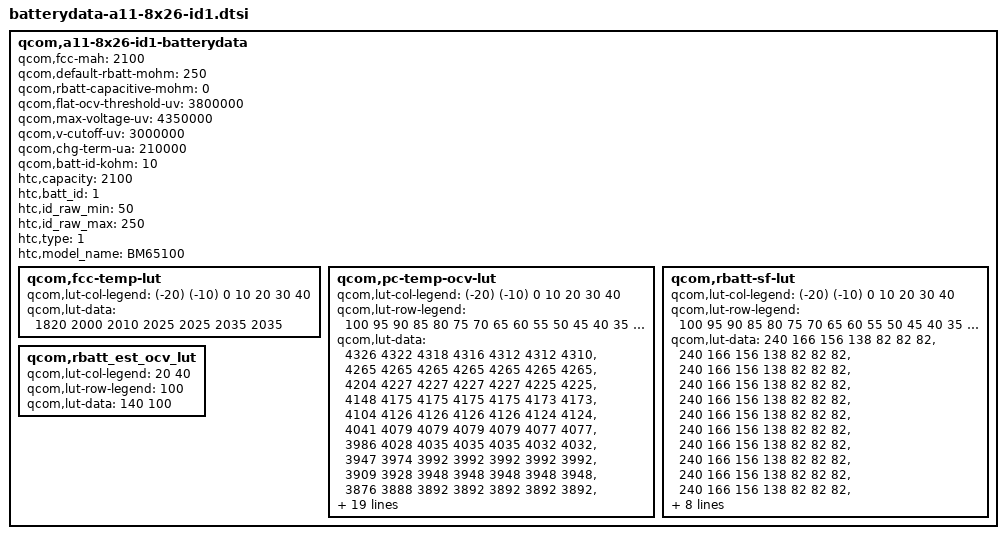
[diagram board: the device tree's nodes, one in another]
qcom,a11-8x26-id1-batterydata {
	qcom,fcc-mah = <2100>;
	qcom,default-rbatt-mohm = <250>;
	qcom,rbatt-capacitive-mohm = <0>;
	qcom,flat-ocv-threshold-uv = <3800000>;
	qcom,max-voltage-uv = <4350000>;
	qcom,v-cutoff-uv = <3000000>;
	qcom,chg-term-ua = <210000>;
	qcom,batt-id-kohm = <10>;
	htc,capacity = <2100>;
	htc,batt_id = <1>;
	htc,id_raw_min = <50>;
	htc,id_raw_max = <250>;
	htc,type = <1>;
	htc,model_name = "BM65100";

	qcom,fcc-temp-lut {
		qcom,lut-col-legend = <(-20) (-10) 0 10 20 30 40>;
		qcom,lut-data = <1820 2000 2010 2025 2025 2035 2035>;
	};

	qcom,pc-temp-ocv-lut {
		qcom,lut-col-legend = <(-20) (-10) 0 10 20 30 40>;
		qcom,lut-row-legend = <100 95 90 85 80 75 70 65 60 55 50 45 40 35 30 25 20 15 10 9 8 7 6 5 4 3 2 1 0>;
		qcom,lut-data = <4326 4322 4318 4316 4312 4312 4310>,
				<4265 4265 4265 4265 4265 4265 4265>,
				<4204 4227 4227 4227 4227 4225 4225>,
				<4148 4175 4175 4175 4175 4173 4173>,
				<4104 4126 4126 4126 4126 4124 4124>,
				<4041 4079 4079 4079 4079 4077 4077>,
				<3986 4028 4035 4035 4035 4032 4032>,
				<3947 3974 3992 3992 3992 3992 3992>,
				<3909 3928 3948 3948 3948 3948 3948>,
				<3876 3888 3892 3892 3892 3892 3892>,
				<3850 3857 3863 3863 3863 3863 3863>,
				<3831 3833 3839 3839 3839 3839 3839>,
				<3817 3818 3818 3818 3818 3818 3818>,
				<3800 3799 3799 3799 3799 3799 3799>,
				<3783 3781 3781 3781 3781 3781 3781>,
				<3763 3766 3766 3759 3750 3750 3750>,
				<3744 3733 3723 3715 3706 3706 3706>,
				<3720 3709 3701 3696 3692 3692 3692>,
				<3676 3686 3678 3667 3650 3650 3650>,
				<3661 3666 3652 3640 3621 3621 3621>,
				<3643 3642 3622 3609 3589 3589 3589>,
				<3622 3613 3584 3570 3548 3548 3548>,
				<3600 3584 3546 3531 3507 3507 3507>,
				<3568 3540 3489 3473 3446 3446 3446>,
				<3555 3515 3458 3435 3412 3412 3412>,
				<3541 3489 3427 3398 3378 3378 3378>,
				<3523 3454 3383 3345 3329 3329 3329>,
				<3494 3398 3315 3262 3254 3254 3254>,
				<3437 3286 3178 3102 3102 3102 3102>;
	};

	qcom,rbatt-sf-lut {
		qcom,lut-col-legend = <(-20) (-10) 0 10 20 30 40>;
		qcom,lut-row-legend = <100 95 90 85 80 75 70 65 60 55 50 45 40 35 30 25 20 15 10>;
		qcom,lut-data = <240 166 156 138 82 82 82>,
				<240 166 156 138 82 82 82>,
				<240 166 156 138 82 82 82>,
				<240 166 156 138 82 82 82>,
				<240 166 156 138 82 82 82>,
				<240 166 156 138 82 82 82>,
				<240 166 156 138 82 82 82>,
				<240 166 156 138 82 82 82>,
				<240 166 156 138 82 82 82>,
				<240 166 156 138 82 82 82>,
				<240 166 156 138 82 82 82>,
				<240 166 156 138 82 82 82>,
				<240 166 156 138 82 82 82>,
				<240 166 156 138 82 82 82>,
				<240 166 156 138 82 82 82>,
				<240 166 156 138 82 82 82>,
				<240 166 156 138 82 82 82>,
				<240 166 156 138 82 82 82>,
				<240 166 156 138 82 82 82>;
	};
	qcom,rbatt_est_ocv_lut {
		qcom,lut-col-legend = <20 40>;
		qcom,lut-row-legend = <100>;
		qcom,lut-data = <140 100>;
	};
};
